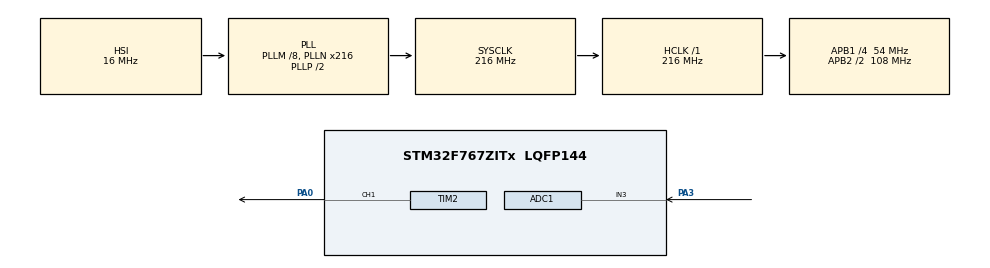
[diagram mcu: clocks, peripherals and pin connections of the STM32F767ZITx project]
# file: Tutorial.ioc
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ADC1.Channel-0\#ChannelRegularConversion=ADC_CHANNEL_3
ADC1.ContinuousConvMode=ENABLE
ADC1.EOCSelection=ADC_EOC_SEQ_CONV
ADC1.NbrOfConversionFlag=1
ADC1.Rank-0\#ChannelRegularConversion=1
ADC1.SamplingTime-0\#ChannelRegularConversion=ADC_SAMPLETIME_3CYCLES
ADC1.master=1
Mcu.Family=STM32F7
Mcu.Name=STM32F767ZITx
Mcu.Package=LQFP144
NVIC.PriorityGroup=NVIC_PRIORITYGROUP_4
PA0/WKUP.Signal=S_TIM2_CH1_ETR
PA3.Signal=ADCx_IN3
ProjectManager.HeapSize=0x200
ProjectManager.StackSize=0x400
ProjectManager.TargetToolchain=STM32CubeIDE
RCC.AHBFreq_Value=216000000
RCC.APB1CLKDivider=RCC_HCLK_DIV4
RCC.APB1Freq_Value=54000000
RCC.APB1TimFreq_Value=108000000
RCC.APB2CLKDivider=RCC_HCLK_DIV2
RCC.APB2Freq_Value=108000000
RCC.APB2TimFreq_Value=216000000
RCC.CortexFreq_Value=216000000
RCC.HCLKFreq_Value=216000000
RCC.HSE_VALUE=25000000
RCC.HSI_VALUE=16000000
RCC.LSE_VALUE=32768
RCC.PLLM=8
RCC.PLLN=216
RCC.SYSCLKFreq_VALUE=216000000
RCC.SYSCLKSource=RCC_SYSCLKSOURCE_PLLCLK
RCC.USBFreq_Value=216000000
RCC.VCOOutputFreq_Value=432000000
SH.ADCx_IN3.0=ADC1_IN3,IN3
SH.S_TIM2_CH1_ETR.0=TIM2_CH1,PWM Generation1 CH1
TIM2.AutoReloadPreload=TIM_AUTORELOAD_PRELOAD_ENABLE
TIM2.Channel-PWM\ Generation1\ CH1=TIM_CHANNEL_1
TIM2.OC1Preload_PWM=DISABLE
TIM2.Period=1000-1
TIM2.Prescaler=108-1
TIM2.Pulse-PWM\ Generation1\ CH1=1000/4 - 1
VP_TIM2_VS_ClockSourceINT.Mode=Internal
board=custom

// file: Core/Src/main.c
/* USER CODE BEGIN Header */
/**
  ******************************************************************************
  * @file           : main.c
  * @brief          : Main program body
  ******************************************************************************
  * @attention
  *
  * Copyright (c) 2023 STMicroelectronics.
  * All rights reserved.
  *
  * This software is licensed under terms that can be found in the LICENSE file
  * in the root directory of this software component.
  * If no LICENSE file comes with this software, it is provided AS-IS.
  *
  ******************************************************************************
  */
/* USER CODE END Header */
#include "main.h"
#include "adc.h"
#include "tim.h"
#include "gpio.h"

/* USER CODE BEGIN Includes */
//#include "ILI9341_GFX.h"
//#include "ILI9341_STM32_Driver.h"
//#include "ILI9341_Touchscreen.h"
/* USER CODE END Includes */

/* USER CODE BEGIN PV */
float dutyCycle = 1.0;
volatile uint32_t adc_val;
uint32_t adc_av8;
uint32_t pwm;
/* USER CODE END PV */

void SystemClock_Config(void);
static void MPU_Initialize(void);
static void MPU_Config(void);
/* USER CODE BEGIN PFP */
uint32_t average_8(uint32_t x);
/* USER CODE END PFP */

int main(void)
{

  /* MCU Configuration--------------------------------------------------------*/

  /* Reset of all peripherals, Initializes the Flash interface and the Systick. */
  HAL_Init();

  /* MPU Configuration--------------------------------------------------------*/
  MPU_Config();

  /* Configure the system clock */
  SystemClock_Config();

  /* Initialize all configured peripherals */
  MX_GPIO_Init();
  MX_TIM2_Init();
  MX_ADC1_Init();
  /* USER CODE BEGIN 2 */
  HAL_TIM_PWM_Start(&htim2, TIM_CHANNEL_1);
  HAL_ADC_Start(&hadc1);
  /* USER CODE END 2 */

  /* Infinite loop */
  while (1)
  {

    /* USER CODE BEGIN 3 */
	  while (HAL_ADC_PollForConversion(&hadc1, 100) != HAL_OK){}
	  adc_val = HAL_ADC_GetValue(&hadc1);

	  dutyCycle = (float)adc_val / 4095.0; //value between 0.xx - 1.00

	  TIM2->CCR1 = (1000-1) * (dutyCycle/100.0);
	  pwm = HAL_GPIO_ReadPin(GPIOA, GPIO_PIN_0);
  }
  /* USER CODE END 3 */
}

void SystemClock_Config(void)
{
  RCC_OscInitTypeDef RCC_OscInitStruct = {0};
  RCC_ClkInitTypeDef RCC_ClkInitStruct = {0};

  /** Configure the main internal regulator output voltage
  */
  __HAL_RCC_PWR_CLK_ENABLE();
  __HAL_PWR_VOLTAGESCALING_CONFIG(PWR_REGULATOR_VOLTAGE_SCALE1);

  /** Initializes the RCC Oscillators according to the specified parameters
  * in the RCC_OscInitTypeDef structure.
  */
  RCC_OscInitStruct.OscillatorType = RCC_OSCILLATORTYPE_HSI;
  RCC_OscInitStruct.HSIState = RCC_HSI_ON;
  RCC_OscInitStruct.HSICalibrationValue = RCC_HSICALIBRATION_DEFAULT;
  RCC_OscInitStruct.PLL.PLLState = RCC_PLL_ON;
  RCC_OscInitStruct.PLL.PLLSource = RCC_PLLSOURCE_HSI;
  RCC_OscInitStruct.PLL.PLLM = 8;
  RCC_OscInitStruct.PLL.PLLN = 216;
  RCC_OscInitStruct.PLL.PLLP = RCC_PLLP_DIV2;
  RCC_OscInitStruct.PLL.PLLQ = 2;
  RCC_OscInitStruct.PLL.PLLR = 2;
  if (HAL_RCC_OscConfig(&RCC_OscInitStruct) != HAL_OK)
  {
    Error_Handler();
  }

  /** Activate the Over-Drive mode
  */
  if (HAL_PWREx_EnableOverDrive() != HAL_OK)
  {
    Error_Handler();
  }

  /** Initializes the CPU, AHB and APB buses clocks
  */
  RCC_ClkInitStruct.ClockType = RCC_CLOCKTYPE_HCLK|RCC_CLOCKTYPE_SYSCLK
                              |RCC_CLOCKTYPE_PCLK1|RCC_CLOCKTYPE_PCLK2;
  RCC_ClkInitStruct.SYSCLKSource = RCC_SYSCLKSOURCE_PLLCLK;
  RCC_ClkInitStruct.AHBCLKDivider = RCC_SYSCLK_DIV1;
  RCC_ClkInitStruct.APB1CLKDivider = RCC_HCLK_DIV4;
  RCC_ClkInitStruct.APB2CLKDivider = RCC_HCLK_DIV2;

  if (HAL_RCC_ClockConfig(&RCC_ClkInitStruct, FLASH_LATENCY_7) != HAL_OK)
  {
    Error_Handler();
  }
}

/* USER CODE BEGIN 4 */
uint32_t average_8(uint32_t x)
{
	static uint32_t samples[8];
	static uint32_t i = 0;
	static uint32_t total = 0;

	total += samples[i];
	samples[i] = x;

	i = (i == 7 ? 0 : i + 1);

	return total >> 3;
}
/* USER CODE END 4 */

/* MPU Configuration */

void MPU_Config(void)
{
  MPU_Region_InitTypeDef MPU_InitStruct = {0};

  /* Disables the MPU */
  HAL_MPU_Disable();

  /** Initializes and configures the Region and the memory to be protected
  */
  MPU_InitStruct.Enable = MPU_REGION_ENABLE;
  MPU_InitStruct.Number = MPU_REGION_NUMBER0;
  MPU_InitStruct.BaseAddress = 0x0;
  MPU_InitStruct.Size = MPU_REGION_SIZE_4GB;
  MPU_InitStruct.SubRegionDisable = 0x87;
  MPU_InitStruct.TypeExtField = MPU_TEX_LEVEL0;
  MPU_InitStruct.AccessPermission = MPU_REGION_NO_ACCESS;
  MPU_InitStruct.DisableExec = MPU_INSTRUCTION_ACCESS_DISABLE;
  MPU_InitStruct.IsShareable = MPU_ACCESS_SHAREABLE;
  MPU_InitStruct.IsCacheable = MPU_ACCESS_NOT_CACHEABLE;
  MPU_InitStruct.IsBufferable = MPU_ACCESS_NOT_BUFFERABLE;

  HAL_MPU_ConfigRegion(&MPU_InitStruct);
  /* Enables the MPU */
  HAL_MPU_Enable(MPU_PRIVILEGED_DEFAULT);

}

void Error_Handler(void)
{
  __disable_irq();
  while (1)
  {
  }
}
